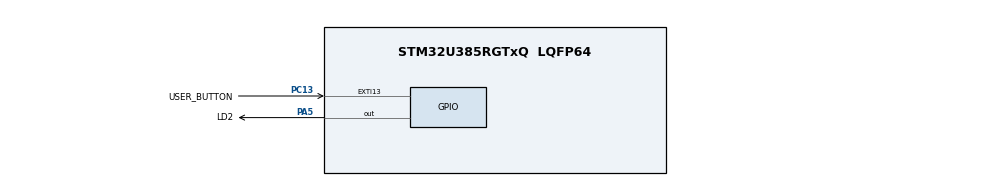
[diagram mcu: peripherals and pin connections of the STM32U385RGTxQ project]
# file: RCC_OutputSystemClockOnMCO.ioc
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CORTEX_M33_NS.userName=CORTEX_M33
Mcu.Family=STM32U3
Mcu.Name=STM32U385RGTxQ
Mcu.Package=LQFP64
NVIC.EXTI13_IRQn=true\:3\:0\:true\:false\:true\:true\:true\:true
NVIC.PriorityGroup=NVIC_PRIORITYGROUP_4
PA5.GPIO_Label=LD2
PA5.Signal=GPIO_Output
PA8.GPIO_PuPd=GPIO_NOPULL
PA8.Signal=RCC_MCO
PC13.GPIO_Label=USER_BUTTON
PC13.GPIO_ModeDefaultEXTI=GPIO_MODE_IT_RISING
PC13.GPIO_PuPd=GPIO_PULLDOWN
PC13.Signal=GPXTI13
PH0-OSC_IN\ (PH0).Mode=HSE-External-Oscillator
PH0-OSC_IN\ (PH0).Signal=RCC_OSC_IN
PH1-OSC_OUT\ (PH1).Mode=HSE-External-Oscillator
PH1-OSC_OUT\ (PH1).Signal=RCC_OSC_OUT
ProjectManager.HeapSize=0x200
ProjectManager.StackSize=0x400
ProjectManager.TargetToolchain=EWARM V9.20
RCC.ADCFreq_Value=96000000
RCC.AHBFreq_Value=96000000
RCC.APB1Freq_Value=96000000
RCC.APB1TimFreq_Value=96000000
RCC.APB2Freq_Value=96000000
RCC.APB2TimFreq_Value=96000000
RCC.APB3Freq_Value=96000000
RCC.CortexFreq_Value=12000000
RCC.HCLKFreq_Value=96000000
RCC.HSE_VALUE=16000000
RCC.HSI48_VALUE=48000000
RCC.HSI_VALUE=16000000
RCC.LSE_VALUE=32768
RCC.LSIDIV_VALUE=32000
RCC.MSISDIV=RCC_MSI_DIV1
RCC.MSI_VALUE=96000000
RCC.PWR_Regulator_Voltage_Scale=PWR_REGULATOR_VOLTAGE_SCALE1
RCC.RCC_MCO1Source=RCC_MCO1SOURCE_HSI48
RCC.SYSCLKFreq_VALUE=96000000
RCC.USBFreq_Value=96000000
VP_ICACHE_VS_ICACHE.Mode=DirectMappedCache
VP_PWR_VS_DBSignals.Mode=DisableDeadBatterySignals
VP_PWR_VS_LPOM.Mode=PowerOptimisation
VP_PWR_VS_SECSignals.Mode=Security/Privilege
board=custom

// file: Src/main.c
/* USER CODE BEGIN Header */
/**
  ******************************************************************************
  * @file    Examples_LL/RCC/RCC_OutputSystemClockOnMCO/Src/main.c
  * @author  MCD Application Team
  * @brief   This example describes how to how to configure MCO pin to output
  *          the system clock through the STM32U3xx RCC LL API.
  ******************************************************************************
  * @attention
  *
  * Copyright (c) 2024 STMicroelectronics.
  * All rights reserved.
  *
  * This software is licensed under terms that can be found in the LICENSE file
  * in the root directory of this software component.
  * If no LICENSE file comes with this software, it is provided AS-IS.
  *
  ******************************************************************************
  */
/* USER CODE END Header */
#include "main.h"

/* USER CODE BEGIN PTD */
/* Structure based on parameters used for MCO config */
typedef struct
{
  uint32_t Source;          /*!< Source of the MCO output */
  uint32_t Prescaler;       /*!< Prescaler applied to MCO output */
} RCC_MCO_ConfigTypeDef;

__IO uint8_t ubButtonPress = 0;
/* USER CODE END PTD */

/* USER CODE BEGIN PD */

/* Number of MCO Config */
#define RCC_MCO_CONFIG_NB   3

/* USER CODE END PD */

/* USER CODE BEGIN PV */

/* Variable to set different MCO config */

static RCC_MCO_ConfigTypeDef aMCO_Config[RCC_MCO_CONFIG_NB] =
{
  {LL_RCC_MCOSOURCE_SYSCLK, LL_RCC_MCO_DIV_1},
  {LL_RCC_MCOSOURCE_HSI48, LL_RCC_MCO_DIV_1},
  {LL_RCC_MCOSOURCE_HSE, LL_RCC_MCO_DIV_1}
};

/* MCO Config index */
__IO uint8_t bMCOIndex = 0;

/* USER CODE END PV */

void SystemClock_Config(void);
static void MX_GPIO_Init(void);
static void MX_ICACHE_Init(void);

int main(void)
{

  /* MCU Configuration--------------------------------------------------------*/

  /* Reset of all peripherals, Initializes the Flash interface and the Systick. */

  /* System interrupt init*/
  NVIC_SetPriorityGrouping(NVIC_PRIORITYGROUP_4);

  /* Configure the system clock */
  SystemClock_Config();

  /* USER CODE BEGIN SysInit */
  /* Enable HSE */
  LL_RCC_HSE_Enable();

   /* Wait till HSE is ready */
  while(LL_RCC_HSE_IsReady() != 1)
  {
  }

  /* Enable HSI48 */
  LL_RCC_HSI48_Enable();

   /* Wait till HSI48 is ready */
  while(LL_RCC_HSI48_IsReady() != 1)
  {
  }
  /* USER CODE END SysInit */

  /* Initialize all configured peripherals */
  MX_GPIO_Init();
  MX_ICACHE_Init();

  /* Infinite loop */
  while (1)
  {

    /* USER CODE BEGIN 3 */
    /* All the process are managed in UserButton_Callback function */
    /* Each time, user press user-button, a new MCO config is set */

  }
  /* USER CODE END 3 */
}

void SystemClock_Config(void)
{
  /** Enable Epod Booster
  */
  LL_AHB1_GRP2_EnableClock(LL_AHB1_GRP2_PERIPH_PWR);
  LL_RCC_SetEPODBoosterClkSource(LL_RCC_EPODBOOSTCLKSRCE_MSIS);
  LL_RCC_SetEPODBoosterClkPrescaler(LL_RCC_EPODBOOSTCLKPRESCAL_1);
  LL_PWR_EnableEPODBooster();
  while(LL_PWR_IsActiveFlag_BOOST() != 1U)
  {
  }

  /** Configure the main internal regulator output voltage
  */
  LL_PWR_SetRegulVoltageScaling(LL_PWR_REGU_VOLTAGE_SCALE1);
  while(LL_PWR_GetRegulCurrentVOS() != LL_PWR_REGU_VOLTAGE_SCALE1)
  {
  }

  /** Set Flash latency before switching to MSIS
  */
  LL_FLASH_SetLatency(LL_FLASH_LATENCY_2);
  while(LL_FLASH_GetLatency() != LL_FLASH_LATENCY_2)
  {
  }

  /** Activate MSIS as source
  */
  LL_RCC_MSIS_SetClockSource(LL_RCC_MSIS_CLOCK_SOURCE_RC0);
  LL_RCC_MSIS_SetClockDivision(LL_RCC_MSIS_CLOCK_SOURCE_RC_DIV_1);
  LL_RCC_MSI_SetMSIxClockRange();
  LL_RCC_SetSysClkSource(LL_RCC_SYS_CLKSOURCE_MSIS);

  /** Wait till System clock is ready
  */
  while(LL_RCC_GetSysClkSource() != LL_RCC_SYS_CLKSOURCE_MSIS)
  {
  }

  LL_RCC_SetAHBPrescaler(LL_RCC_HCLK_SYSCLK_DIV_1);
  LL_RCC_SetAPB1Prescaler(LL_RCC_APB1_HCLK_DIV_1);
  LL_RCC_SetAPB2Prescaler(LL_RCC_APB2_HCLK_DIV_1);
  LL_RCC_SetAPB3Prescaler(LL_RCC_APB3_HCLK_DIV_1);

  LL_Init1msTick(96000000);

  LL_SetSystemCoreClock(96000000);
}

static void MX_ICACHE_Init(void)
{

  /** Enable instruction cache in 1-way (direct mapped cache)
  */
  LL_ICACHE_SetMode(LL_ICACHE_1WAY);
  LL_ICACHE_Enable();

}

static void MX_GPIO_Init(void)
{
  LL_EXTI_InitTypeDef EXTI_InitStruct = {0};
  LL_GPIO_InitTypeDef GPIO_InitStruct = {0};

  /* GPIO Ports Clock Enable */
  LL_AHB2_GRP1_EnableClock(LL_AHB2_GRP1_PERIPH_GPIOC);
  LL_AHB2_GRP1_EnableClock(LL_AHB2_GRP1_PERIPH_GPIOH);
  LL_AHB2_GRP1_EnableClock(LL_AHB2_GRP1_PERIPH_GPIOA);

  /**/
  LL_GPIO_ResetOutputPin(LD2_GPIO_Port, LD2_Pin);

  /**/
  LL_EXTI_SetEXTISource(LL_EXTI_CONFIG_PORTC, LL_EXTI_CONFIG_LINE13);

  /**/
  EXTI_InitStruct.Line_0_31 = LL_EXTI_LINE_13;
  EXTI_InitStruct.LineCommand = ENABLE;
  EXTI_InitStruct.Mode = LL_EXTI_MODE_IT;
  EXTI_InitStruct.Trigger = LL_EXTI_TRIGGER_RISING;
  LL_EXTI_Init(&EXTI_InitStruct);

  /**/
  LL_GPIO_SetPinPull(USER_BUTTON_GPIO_Port, USER_BUTTON_Pin, LL_GPIO_PULL_DOWN);

  /**/
  LL_GPIO_SetPinMode(USER_BUTTON_GPIO_Port, USER_BUTTON_Pin, LL_GPIO_MODE_INPUT);

  /**/
  GPIO_InitStruct.Pin = LD2_Pin;
  GPIO_InitStruct.Mode = LL_GPIO_MODE_OUTPUT;
  GPIO_InitStruct.Speed = LL_GPIO_SPEED_FREQ_LOW;
  GPIO_InitStruct.OutputType = LL_GPIO_OUTPUT_PUSHPULL;
  GPIO_InitStruct.Pull = LL_GPIO_PULL_NO;
  LL_GPIO_Init(LD2_GPIO_Port, &GPIO_InitStruct);

  /**/
  GPIO_InitStruct.Pin = LL_GPIO_PIN_8;
  GPIO_InitStruct.Mode = LL_GPIO_MODE_ALTERNATE;
  GPIO_InitStruct.Speed = LL_GPIO_SPEED_FREQ_HIGH;
  GPIO_InitStruct.OutputType = LL_GPIO_OUTPUT_PUSHPULL;
  GPIO_InitStruct.Pull = LL_GPIO_PULL_NO;
  GPIO_InitStruct.Alternate = LL_GPIO_AF_0;
  LL_GPIO_Init(GPIOA, &GPIO_InitStruct);

  /* EXTI interrupt init*/
  NVIC_SetPriority(EXTI13_IRQn, NVIC_EncodePriority(NVIC_GetPriorityGrouping(),3, 0));
  NVIC_EnableIRQ(EXTI13_IRQn);

}

/* USER CODE BEGIN 4 */

/******************************************************************************/
/*   USER IRQ HANDLER TREATMENT                                               */
/******************************************************************************/
/**
  * @brief  Function to manage User button press
  * @param  None
  * @retval None
  */
void UserButton_Callback(void)
{
  register uint32_t source = 0, prescaler = 0;

  /* Get the MCO config to apply */
  source = aMCO_Config[bMCOIndex].Source;
  prescaler = aMCO_Config[bMCOIndex].Prescaler;

  /* Toggle LD2 to indicate a button press*/
  LL_GPIO_TogglePin(LD2_GPIO_Port, LD2_Pin);
  ubButtonPress = 1;

  /* Select MCO clock source and prescaler */
  LL_RCC_SetSourceClockMCO(source);
  LL_RCC_SetClockPrescalerMCO(prescaler);
  //LL_RCC_ConfigMCO(source, prescaler);

  /* Set new MCO config Index */
  bMCOIndex = (bMCOIndex + 1) % RCC_MCO_CONFIG_NB;
}

/* USER CODE END 4 */

void Error_Handler(void)
{
  while (1)
  {
  }
}
